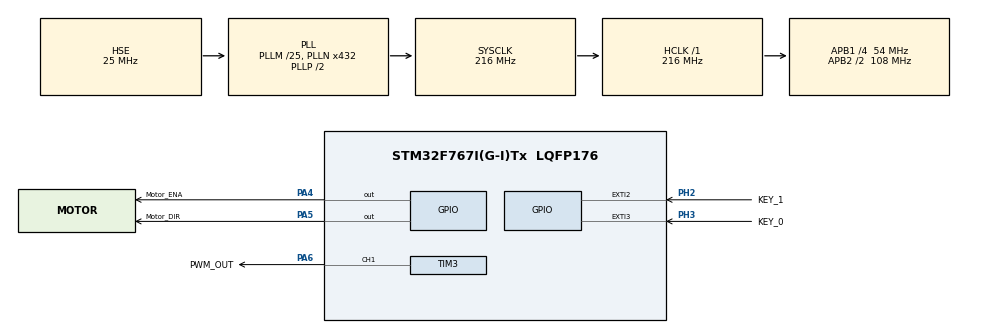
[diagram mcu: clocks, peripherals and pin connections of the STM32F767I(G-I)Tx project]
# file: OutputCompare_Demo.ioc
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Mcu.Family=STM32F7
Mcu.Name=STM32F767I(G-I)Tx
Mcu.Package=LQFP176
NVIC.EXTI2_IRQn=true\:1\:0\:true\:false\:true\:true\:true
NVIC.EXTI3_IRQn=true\:1\:0\:true\:false\:true\:true\:true
NVIC.PriorityGroup=NVIC_PRIORITYGROUP_4
NVIC.TIM3_IRQn=true\:1\:0\:true\:false\:true\:true\:true
PA13.Mode=Trace_Asynchronous_SW
PA13.Signal=SYS_JTMS-SWDIO
PA14.Mode=Trace_Asynchronous_SW
PA14.Signal=SYS_JTCK-SWCLK
PA4.GPIO_Label=Motor_ENA
PA4.GPIO_ModeDefaultOutputPP=GPIO_MODE_OUTPUT_PP
PA4.GPIO_PuPd=GPIO_PULLUP
PA4.GPIO_Speed=GPIO_SPEED_FREQ_VERY_HIGH
PA4.PinState=GPIO_PIN_RESET
PA4.Signal=GPIO_Output
PA5.GPIO_Label=Motor_DIR
PA5.GPIO_ModeDefaultOutputPP=GPIO_MODE_OUTPUT_PP
PA5.GPIO_PuPd=GPIO_PULLUP
PA5.GPIO_Speed=GPIO_SPEED_FREQ_VERY_HIGH
PA5.PinState=GPIO_PIN_RESET
PA5.Signal=GPIO_Output
PA6.GPIO_Label=PWM_OUT
PA6.GPIO_PuPd=GPIO_PULLDOWN
PA6.GPIO_Speed=GPIO_SPEED_FREQ_VERY_HIGH
PA6.Signal=S_TIM3_CH1
PB3.Mode=Trace_Asynchronous_SW
PB3.Signal=SYS_JTDO-SWO
PH0/OSC_IN.Mode=HSE-External-Oscillator
PH0/OSC_IN.Signal=RCC_OSC_IN
PH1/OSC_OUT.Mode=HSE-External-Oscillator
PH1/OSC_OUT.Signal=RCC_OSC_OUT
PH2.GPIO_Label=KEY_1
PH2.GPIO_ModeDefaultEXTI=GPIO_MODE_IT_FALLING
PH2.GPIO_PuPd=GPIO_PULLUP
PH2.Signal=GPXTI2
PH3.GPIO_Label=KEY_0
PH3.GPIO_ModeDefaultEXTI=GPIO_MODE_IT_FALLING
PH3.GPIO_PuPd=GPIO_PULLUP
PH3.Signal=GPXTI3
ProjectManager.HeapSize=0x200
ProjectManager.StackSize=0x400
ProjectManager.TargetToolchain=STM32CubeIDE
RCC.AHBFreq_Value=216000000
RCC.APB1CLKDivider=RCC_HCLK_DIV4
RCC.APB1Freq_Value=54000000
RCC.APB1TimFreq_Value=108000000
RCC.APB2CLKDivider=RCC_HCLK_DIV2
RCC.APB2Freq_Value=108000000
RCC.APB2TimFreq_Value=216000000
RCC.CortexFreq_Value=216000000
RCC.HCLKFreq_Value=216000000
RCC.HSE_VALUE=25000000
RCC.HSI_VALUE=16000000
RCC.LSE_VALUE=32768
RCC.PLLM=25
RCC.PLLN=432
RCC.PLLSourceVirtual=RCC_PLLSOURCE_HSE
RCC.SYSCLKFreq_VALUE=216000000
RCC.SYSCLKSource=RCC_SYSCLKSOURCE_PLLCLK
RCC.USBFreq_Value=216000000
RCC.VCOOutputFreq_Value=432000000
SH.S_TIM3_CH1.0=TIM3_CH1,Output Compare1 CH1
TIM3.Channel-Output\ Compare1\ CH1=TIM_CHANNEL_1
TIM3.OCMode_1=TIM_OCMODE_TOGGLE
TIM3.OCPolarity_1=TIM_OCPOLARITY_LOW
TIM3.Period=999
TIM3.Prescaler=107
TIM3.Pulse-Output\ Compare1\ CH1=499
board=custom

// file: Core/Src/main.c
/* USER CODE BEGIN Header */
/**
  ******************************************************************************
  * @file           : main.c
  * @brief          : Main program body
  ******************************************************************************
  * @attention
  *
  * <h2><center>&copy; Copyright (c) 2020 STMicroelectronics.
  * All rights reserved.</center></h2>
  *
  * This software component is licensed by ST under BSD 3-Clause license,
  * the "License"; You may not use this file except in compliance with the
  * License. You may obtain a copy of the License at:
  *                        opensource.org/licenses/BSD-3-Clause
  *
  ******************************************************************************
  */
/* USER CODE END Header */
#include "main.h"
#include "tim.h"
#include "gpio.h"

/* USER CODE BEGIN PV */
uint32_t Pulse_Count = 0;
/* USER CODE END PV */

void SystemClock_Config(void);

int main(void)
{

  /* MCU Configuration--------------------------------------------------------*/

  /* Reset of all peripherals, Initializes the Flash interface and the Systick. */
  HAL_Init();

  /* Configure the system clock */
  SystemClock_Config();

  /* Initialize all configured peripherals */
  MX_GPIO_Init();
  MX_TIM3_Init();
  /* USER CODE BEGIN 2 */
  HAL_GPIO_WritePin(PWM_OUT_GPIO_Port, PWM_OUT_Pin, GPIO_PIN_RESET);
  /* USER CODE END 2 */

  /* Infinite loop */
  while (1)
  {

  }
}

void SystemClock_Config(void)
{
  RCC_OscInitTypeDef RCC_OscInitStruct = {0};
  RCC_ClkInitTypeDef RCC_ClkInitStruct = {0};

  /** Configure the main internal regulator output voltage
  */
  __HAL_RCC_PWR_CLK_ENABLE();
  __HAL_PWR_VOLTAGESCALING_CONFIG(PWR_REGULATOR_VOLTAGE_SCALE1);
  /** Initializes the RCC Oscillators according to the specified parameters
  * in the RCC_OscInitTypeDef structure.
  */
  RCC_OscInitStruct.OscillatorType = RCC_OSCILLATORTYPE_HSE;
  RCC_OscInitStruct.HSEState = RCC_HSE_ON;
  RCC_OscInitStruct.PLL.PLLState = RCC_PLL_ON;
  RCC_OscInitStruct.PLL.PLLSource = RCC_PLLSOURCE_HSE;
  RCC_OscInitStruct.PLL.PLLM = 25;
  RCC_OscInitStruct.PLL.PLLN = 432;
  RCC_OscInitStruct.PLL.PLLP = RCC_PLLP_DIV2;
  RCC_OscInitStruct.PLL.PLLQ = 2;
  if (HAL_RCC_OscConfig(&RCC_OscInitStruct) != HAL_OK)
  {
    Error_Handler();
  }
  /** Activate the Over-Drive mode
  */
  if (HAL_PWREx_EnableOverDrive() != HAL_OK)
  {
    Error_Handler();
  }
  /** Initializes the CPU, AHB and APB buses clocks
  */
  RCC_ClkInitStruct.ClockType = RCC_CLOCKTYPE_HCLK|RCC_CLOCKTYPE_SYSCLK
                              |RCC_CLOCKTYPE_PCLK1|RCC_CLOCKTYPE_PCLK2;
  RCC_ClkInitStruct.SYSCLKSource = RCC_SYSCLKSOURCE_PLLCLK;
  RCC_ClkInitStruct.AHBCLKDivider = RCC_SYSCLK_DIV1;
  RCC_ClkInitStruct.APB1CLKDivider = RCC_HCLK_DIV4;
  RCC_ClkInitStruct.APB2CLKDivider = RCC_HCLK_DIV2;

  if (HAL_RCC_ClockConfig(&RCC_ClkInitStruct, FLASH_LATENCY_7) != HAL_OK)
  {
    Error_Handler();
  }
}

void Error_Handler(void)
{
}

/************************ (C) COPYRIGHT STMicroelectronics *****END OF FILE****/
